AUTOSAR XML (schema 4-2-2)
package /ComponentTypes
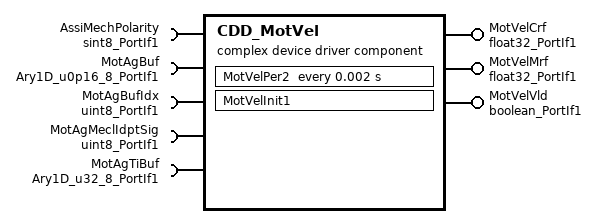
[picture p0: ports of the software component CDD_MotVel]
  complex device driver sw component type CDD_MotVel
    provide port MotVelCrf: nonqueued-sender-com-spec{data-element=Val, init-value=0}, provided-interface=float32_PortIf1
    provide port MotVelMrf: nonqueued-sender-com-spec{data-element=Val, init-value=0}, provided-interface=float32_PortIf1
    provide port MotVelVld: nonqueued-sender-com-spec{data-element=Logl, init-value=1}, provided-interface=boolean_PortIf1
    5 x require port:
      AssiMechPolarity: nonqueued-receiver-com-spec{data-element=Val, filter=data-filter-type=ALWAYS, init-value=1}, required-interface=sint8_PortIf1
      MotAgBuf: nonqueued-receiver-com-spec{data-element=Ary1D, filter=data-filter-type=ALWAYS, init-value=8 x 0}, required-interface=Ary1D_u0p16_8_PortIf1
      MotAgBufIdx: nonqueued-receiver-com-spec{data-element=Val, filter=data-filter-type=ALWAYS, init-value=0}, required-interface=uint8_PortIf1
      MotAgMeclIdptSig: nonqueued-receiver-com-spec{data-element=Val, filter=data-filter-type=ALWAYS, init-value=3}, required-interface=uint8_PortIf1
      MotAgTiBuf: nonqueued-receiver-com-spec{data-element=Ary1D, filter=data-filter-type=ALWAYS, init-value=[0, 62, 125, 187, 250, 312, 375, 437]}, required-interface=Ary1D_u32_8_PortIf1
    behavior CDD_MotVel_InternalBehavior
      ar-typed-per-instance-memorys:
        8 x data, all with sw-calibration-access=READ-ONLY:
          dMotVelAvrgTi: type=float32
          dMotVelMotAgRef: type=u0p16
          dMotVelTiStampRef: type=float32
          MotAgBufIdxPrev: type=uint8
          MotAgBufIdxPrim: type=uint8
          MotAgBufPrev: type=Ary1D_u0p16_8
          MotAgTiBufPrev: type=Ary1D_u32_8
          MotVelIninCntr: type=uint8
      init event CDD_MotVel_InitEvent: start-on-event=MotVelInit1
      timing event TMT_MotVelPer2: start-on-event=MotVelPer2, period=0.002
      port-api-options:
        enable-take-address=false, error-handling=NO-TRANSFORMER-ERROR-HANDLING, indirect-api=false, port=AssiMechPolarity
        enable-take-address=false, error-handling=NO-TRANSFORMER-ERROR-HANDLING, indirect-api=false, port=MotAgBuf
        enable-take-address=false, error-handling=NO-TRANSFORMER-ERROR-HANDLING, indirect-api=false, port=MotAgBufIdx
        enable-take-address=false, error-handling=NO-TRANSFORMER-ERROR-HANDLING, indirect-api=false, port=MotAgMeclIdptSig
        enable-take-address=false, error-handling=NO-TRANSFORMER-ERROR-HANDLING, indirect-api=false, port=MotAgTiBuf
        enable-take-address=false, error-handling=NO-TRANSFORMER-ERROR-HANDLING, indirect-api=false, port=MotVelCrf
        enable-take-address=false, error-handling=NO-TRANSFORMER-ERROR-HANDLING, indirect-api=false, port=MotVelMrf
      runnable MotVelInit1
      runnable MotVelPer2
        data-receive-point-by-arguments:
          5 x access:
            REC_AssiMechPolarity_Val: accessed-variable=AssiMechPolarity.Val
            REC_MotAgBuf_Ary1D: accessed-variable=MotAgBuf.Ary1D
            REC_MotAgBufIdx_Val: accessed-variable=MotAgBufIdx.Val
            REC_MotAgMeclIdptSig_Val: accessed-variable=MotAgMeclIdptSig.Val
            REC_MotAgTiBuf_Ary1D: accessed-variable=MotAgTiBuf.Ary1D
        data-send-points:
          access SEND_MotVelCrf_Val: accessed-variable=MotVelCrf.Val
          access SEND_MotVelMrf_Val: accessed-variable=MotVelMrf.Val
          access SEND_MotVelVld_Logl: accessed-variable=MotVelVld.Logl
  swc implementation CDD_MotVel_Implementation: behavior=CDD_MotVel_InternalBehavior
    code-descriptors:
      code Default: artifact-descriptors=autosar-engineering-object={short-label=Default, category=SWSRC}
